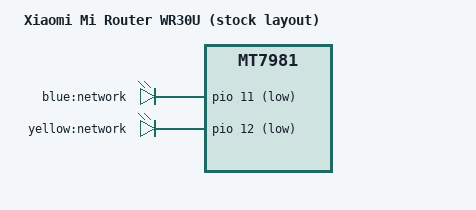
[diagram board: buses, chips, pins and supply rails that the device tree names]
// SPDX-License-Identifier: GPL-2.0-or-later OR MIT

/dts-v1/;
#include "mt7981-xiaomi-mi-router.dtsi"

/ { 
	model = "Xiaomi Mi Router WR30U (stock layout)";
	compatible = "xiaomi,mi-router-wr30u-stock", "mediatek,mt7981";
};

&leds {
	led_network_blue {
		label = "blue:network";
		gpios = <&pio 11 GPIO_ACTIVE_LOW>;
	};

	led_network_yellow {
		label = "yellow:network";
		gpios = <&pio 12 GPIO_ACTIVE_LOW>;
	};
};

&partitions {
	// ubi_kernel is the ubi partition in stock.
	partition@600000 {
		label = "ubi_kernel";
		reg = <0x600000 0x2200000>;
	};

	/* ubi is the result of squashing
	 * consecutive stock partitions:
	 * - ubi1
	 * - overlay
	 * - data
	 */
	partition@2800000 {
		label = "ubi";
		reg = <0x2800000 0x4e00000>;
	};

	partition@7600000 {
		label = "KF";
		reg = <0x7600000 0x40000>;
	};
};
